# EMIF register map
Vendor: Texas Instruments
Registers are 32-bit, access per field, reset 0x0 unless marked. A register's access mark holds for its fields unless they carry their own. Offsets are as the file gives them; [hi:lo] are bit positions.

## EMIF (part 2 of 2)
0x00 EMIF_REVISION ro reset not defined — Revision number register
  [31:0] REVISION — Module revision
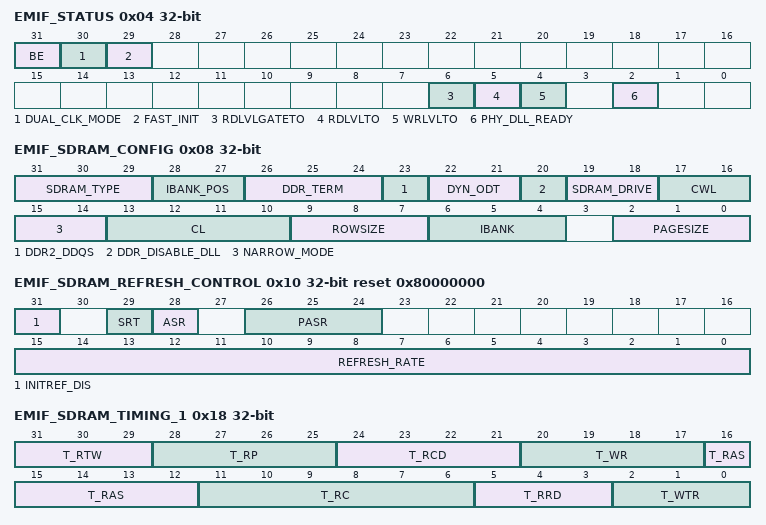
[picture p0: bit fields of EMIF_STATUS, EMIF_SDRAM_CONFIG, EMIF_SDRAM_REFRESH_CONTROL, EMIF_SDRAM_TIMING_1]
0x04 EMIF_STATUS ro — SDRAM Status Register (STATUS)
  [31] BE — Big endian mode select for 8 and 16-bit devices, set to 1 for big endian or 0 for little endian operation. In current implementation, only 32-bit devices are supported - this bit is don't care.
  [30] DUAL_CLK_MODE — Dual Clock mode. Defines whether the EMIF_L3_ICLK and EMIF_FICLK clock are asynchronous. EMIF_L3_ICLK and EMIF_FICLK clock are asynchronous, if set to 1.
  [29] FAST_INIT — Fast Init. Defines whether the EMIF fast initialization mode has been enabled. Fast initialization is enabled if set to 1.
  [6] RDLVLGATETO — Read DQS Gate Training Timeout. Value of 1 indicates read DQS gate training has timed out because read DQS gate training done was not received from the PHY.
  [5] RDLVLTO — Read Data Eye Training Timeout. Value of 1 indicates read data eye training has timed out because read data eye training done was not received from the PHY.
  [4] WRLVLTO — Write Leveling Timeout. Value of 1 indicates write leveling has timed out because write leveling done was not received from the PHY.
  [2] PHY_DLL_READY — DDR PHY Ready. The DDR PHY is ready for normal operation, if set to 1.
0x08 EMIF_SDRAM_CONFIG — SDRAM Config Register. A write to this register will cause the EMIF to start the SDRAM initialization sequence. CAUTION: This register is loaded with values by control module at device reset.
  [31:29] SDRAM_TYPE rw — SDRAM Type selection. This field is loaded from e-fuse. Set to 2 for DDR2 Set to 3 for DDR3 Set to 4 for LPDDR2 All other values are reserved.
  [28:27] IBANK_POS rw — Internal bank position. See , SDRAM Address Mapping.
  [26:24] DDR_TERM rw — DDR3 termination resistor value. Set to 0 to disable termination. For DDR3, set to 1 for RZQ/4, set to 2 for RZQ/2, set to 3 for RZQ/6, set to 4 for RZQ/12, and set to 5 for RZQ/8. All other values are reserved.
  [23] DDR2_DDQS rw — Differential DQS enable. Set to 0 for single ended DQS (Not supported). Set to 1 for differential DQS.
  [22:21] DYN_ODT rw — DDR3 Dynamic ODT.Not supported. Set to 0 to turn off dynamic ODT.
  [20] DDR_DISABLE_DLL rw — Disable DLL select. Set to 1 to disable DLL inside SDRAM.
  [19:18] SDRAM_DRIVE rw — SDRAM drive strength. For DDR2, set to 0 for normal, and set to 1 for weak drive strength. For DDR3, set to 0 for RZQ/6 and set to 1 for RZQ/7. All other values are reserved.
  [17:16] CWL rw — DDR3 CAS Write latency. Value of 0, 1, 2, and 3 (CAS write latency of 5, 6, 7, and 8) are supported. Use the lowest value supported for best performance. All other values are reserved.
  [15:14] NARROW_MODE rw — SDRAM data bus width. Set to 0 for 32-bit data bus width. Set to 1 for 16-bit data bus width. All other values are reserved.
  [13:10] CL rw — CAS Latency (referred to as read latency (RL) in some SDRAM specs). The value of this field defines the CAS latency to be used when accessing connected SDRAM devices. Values of 2, 3, 4 and 5 (CAS latency of 2, 3, 4 and 5) are supported for DDR2. Values of 2, 4, 6, 8, 10, 12 and 14 (CAS latency of 5, 6, 7, 8, 9, 10 and 11) are supported for DDR3. Values of 3, 4, 5, 6, 7, and 8 (CAS latency of 3, 4, 5, 6, 7, and 8) are supported for LPDDR2-SDRAM. The write latency (WL) is tied to the RL for the LPDDR2. See the LPDDR2 SDRAM standard. All other values are reserved.
  [9:7] ROWSIZE rw — Row Size. Defines the number of row address bits of connected SDRAM devices. Set to 0 for 9 row bits, Set to 1 for 10 row bits, Set to 2 for 11 row bits, Set to 3 for 12 row bits, Set to 4 for 13 row bits, Set to 5 for 14 row bits, Set to 6 for 15 row bits, Set to 7 for 16 row bits. This field is only used when EMIF_SDRAM_CONFIG[28:27] IBANK_POS field is set to 1, 2, or 3 or EBANK_POS field in EMIF_SDRAM_CONFIG_2 register is set to 1.
  [6:4] IBANK rw — Internal Bank setup. Defines number of banks inside connected SDRAM devices. Set to 0 for 1 bank, Set to 1 for 2 banks, Set to 2 for 4 banks, Set to 3 for 8 banks. All other values are reserved.
  [2:0] PAGESIZE rw — Page Size. Defines the internal page size of connected SDRAM devices. Set to 0 for 256-word page (8 column bits), Set to 1 for 512-word page (9 column bits), Set to 2 for 1024-word page (10 column bits), Set to 3 for 2048-word page (11 column bits). All other values are reserved.
0x0C EMIF_SDRAM_CONFIG_2 — SDRAM Config Register 2 CAUTION: This register is loaded with values by control module at device reset.
  [27] EBANK_POS rw — External bank position. Set to 0 to assign external bank address bits from lower OCP address. Set to 1 to assign external bank address bits from higher OCP address bits. See, SDRAM Address Mapping.
0x10 EMIF_SDRAM_REFRESH_CONTROL reset 0x80000000 — SDRAM Refresh Control Register
  [31] INITREF_DIS rw — Initialization and Refresh disable. When set to 1, EMIF will disable SDRAM initialization and refreshes, but will carry out SDRAM write/read transactions.
  [29] SRT rw — DDR3 Self Refresh temperature range. Set to 0 for normal operating temperature range and set to 1 for extended operating temperature range when the ASR field is set to 0. This bit must be set to 0 if the ASR field is set to 1. A write to this field will cause the EMIF to start the SDRAM initialization sequence.
  [28] ASR rw — DDR3 Auto Self Refresh enable. Set to 1 for auto Self Refresh enable. Set to 0 for manual Self Refresh reference indicated by the SRT field. A write to this field will cause the EMIF to start the SDRAM initialization sequence.
  [26:24] PASR rw — Partial Array Self Refresh. These bits get loaded into the Extended Mode Register of DDR3 during initialization. For DDR3, set to 0 for full array, set to 1 or 5 for 1/2 array, set to 2 or 6 for 1/4 array, set to 3 or 7 for 1/8 array, and set to 4 for 3/4 array to be refreshed. All other values are reserved. A write to this field will cause the EMIF to start the SDRAM initialization sequence.
  [15:0] REFRESH_RATE rw — Refresh Rate. Value in this field is used to define the rate at which connected SDRAM devices will be refreshed. SDRAM refresh rate = REFRESH_RATE / EMIF_PHY_FCLK. A 533-MHz DDR clock rate system that requires a 7.8 µs refresh rate would need 7.8 × 533 = 4157 or 0x103D value to be written. To avoid lock-up situations, the programmer must not program REFRESH_RATE &lt; (6 × EMIF_SDRAM_TIMING_3[12:4] T_RFC).
0x14 EMIF_SDRAM_REFRESH_CONTROL_SHADOW — SDRAM Refresh Control Shadow Register
  [15:0] REFRESH_RATE_SHDW rw — Shadow field for REFRESH_RATE. This field is loaded intoEMIF_SDRAM_REFRESH_CONTROL[15:0] REFRESH_RATE field when SIdleAck is asserted.
0x18 EMIF_SDRAM_TIMING_1 rw — SDRAM Timing 1 Register. If this register is byte written, care must be taken that all the fields are written before performing any accesses to the SDRAM.
  [31:29] T_RTW — Minimum number of DDR clock cycles between Read to Write data phases, minus one.
  [28:25] T_RP — Minimum number of DDR clock cycles from Precharge to Activate or Refresh, minus one.
  [24:21] T_RCD — Minimum number of DDR clock cycles from Activate to Read or Write, minus one.
  [20:17] T_WR — Minimum number of DDR clock cycles from last Write transfer to Precharge, minus one.
  [16:12] T_RAS — Minimum number of DDR clock cycles from Activate to Precharge, minus one. T_RAS value needs to be bigger than or equal to T_RDC value.
  [11:6] T_RC — Minimum number of DDR clock cycles from Activate to Activate, minus one.
  [5:3] T_RRD — Minimum number of DDR clock cycles from Activate to Activate for a different bank, minus one. For an 8-bank, this field must be equal to ((tFAW / (4 × tCK)) - 1).
  [2:0] T_WTR — Minimum number of DDR clock cycles from last Write to Read, minus one.
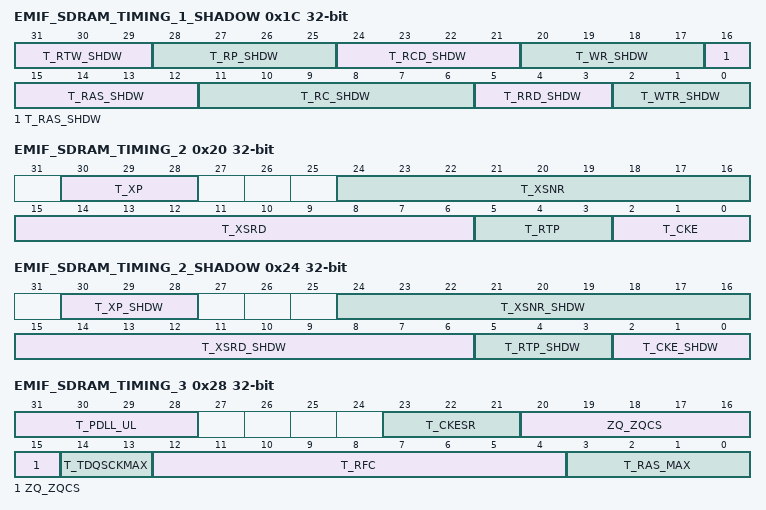
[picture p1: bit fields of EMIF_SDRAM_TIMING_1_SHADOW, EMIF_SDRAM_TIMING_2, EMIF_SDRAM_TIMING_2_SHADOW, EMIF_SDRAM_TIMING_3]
0x1C EMIF_SDRAM_TIMING_1_SHADOW rw — SDRAM Timing 1 Shadow Register
  [31:29] T_RTW_SHDW — Shadow field for T_RTW. This field is loaded intoEMIF_SDRAM_TIMING_1[31:29] T_RTW field when SIdleAck is asserted.
  [28:25] T_RP_SHDW — Shadow field for T_RP. This field is loaded intoEMIF_SDRAM_TIMING_1[28:25] T_RP field when SIdleAck is asserted.
  [24:21] T_RCD_SHDW — Shadow field for T_RCD. This field is loaded intoEMIF_SDRAM_TIMING_1[24:21] T_RCD field when SIdleAck is asserted.
  [20:17] T_WR_SHDW — Shadow field for T_WR. This field is loaded intoEMIF_SDRAM_TIMING_1[20:17] T_WR field when SIdleAck is asserted.
  [16:12] T_RAS_SHDW — Shadow field for T_RAS. This field is loaded intoEMIF_SDRAM_TIMING_1[16:12] T_RAS field when SIdleAck is asserted.
  [11:6] T_RC_SHDW — Shadow field for T_RC. This field is loaded intoEMIF_SDRAM_TIMING_1[11:6] T_RC field when SIdleAck is asserted.
  [5:3] T_RRD_SHDW — Shadow field for T_RRD. This field is loaded intoEMIF_SDRAM_TIMING_1[5:3] T_RRD field when SIdleAck is asserted.
  [2:0] T_WTR_SHDW — Shadow field for T_WTR. This field is loaded intoEMIF_SDRAM_TIMING_1[2:0] T_WTR field when SIdleAck is asserted.
0x20 EMIF_SDRAM_TIMING_2 — SDRAM Timing 2 Register. If this register is byte written, care must be taken that all the fields are written before performing any accesses to the SDRAM.
  [30:28] T_XP rw — Minimum number of DDR clock cycles from power-down exit to any command other than a read command, minus one.
  [24:16] T_XSNR rw — Minimum number of DDR clock cycles from Self-Refresh exit to any command other than a Read command, minus one.
  [15:6] T_XSRD rw — Minimum number of DDR clock cycles from Self-Refresh exit to a Read command, minus one.
  [5:3] T_RTP rw — Minimum number of DDR clock cycles for the last read command to a Precharge command, minus one.
  [2:0] T_CKE rw — Minimum number of DDR clock cycles between CKE pin changes, minus one.
0x24 EMIF_SDRAM_TIMING_2_SHADOW — SDRAM Timing 2 Shadow Register
  [30:28] T_XP_SHDW rw — Shadow field for T_XP. This field is loaded intoEMIF_SDRAM_TIMING_2[30:28] T_XP field when SIdleAck is asserted.
  [24:16] T_XSNR_SHDW rw — Shadow field for T_XSNR. This field is loaded intoEMIF_SDRAM_TIMING_2[24:16] T_XSNR field when SIdleAck is asserted.
  [15:6] T_XSRD_SHDW rw — Shadow field for T_XSRD. This field is loaded intoEMIF_SDRAM_TIMING_2[15:6] T_XSRD field when SIdleAck is asserted.
  [5:3] T_RTP_SHDW rw — Shadow field for T_RTP. This field is loaded intoEMIF_SDRAM_TIMING_2[5:3] T_RTP field when SIdleAck is asserted.
  [2:0] T_CKE_SHDW rw — Shadow field for T_CKE. This field is loaded intoEMIF_SDRAM_TIMING_2[2:0] T_CKE field when SIdleAck is asserted.
0x28 EMIF_SDRAM_TIMING_3 — SDRAM Timing 3 Register. If this register is byte written, care must be taken that all the fields are written before performing any accesses to the SDRAM.
  [31:28] T_PDLL_UL rw — Minimum number of DDR clock cycles for PHY DLL to unlock. A value of N will be equal to N x 128 clocks.
  [23:21] T_CKESR rw — Minimum number of DDR clock cycles for which SDRAM must remain in Self Refresh, minus one.
  [20:15] ZQ_ZQCS rw — Number of DDR clock cycles for a ZQCS command, minus one.
  [14:13] T_TDQSCKMAX rw — Number of DDR clock that satisfies tDQSCKmax for LPDDR2, minus one.
  [12:4] T_RFC rw — Minimum number of DDR clock cycles from Refresh or Load Mode to Refresh or Activate, minus one.
  [3:0] T_RAS_MAX rw — Maximum number of REFRESH_RATE intervals from Activate to Precharge command. This field must be equal to ((tRASmax / tREFI)-1) rounded down to the next lower integer. Value for T_RAS_MAX can be calculated as follows: If tRASmax = 120 us and tREFI = 15.7 us, then T_RAS_MAX = ((120/15.7)-1) = 6.64. Round down to the next lower integer. Therefore, the programmed value must be 6.
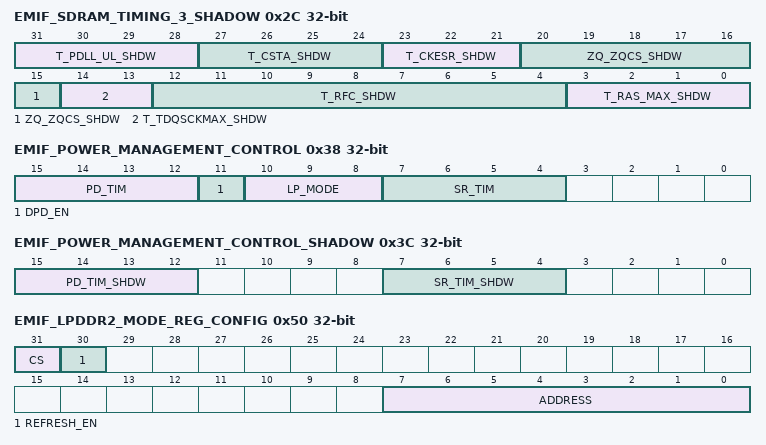
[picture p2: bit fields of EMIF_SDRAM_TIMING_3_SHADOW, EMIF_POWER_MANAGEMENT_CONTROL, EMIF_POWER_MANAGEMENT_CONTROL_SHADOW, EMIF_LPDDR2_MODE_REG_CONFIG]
0x2C EMIF_SDRAM_TIMING_3_SHADOW rw — SDRAM Timing 3 Shadow Register
  [31:28] T_PDLL_UL_SHDW — Shadow field for T_PDLL_UL. This field is loaded into T_PDLL_UL field inEMIF_SDRAM_TIMING_3 register when SIdleAck is asserted.
  [27:24] T_CSTA_SHDW — Shadow field for T_CSTA. This field is loaded into T_CSTA field inEMIF_SDRAM_TIMING_3 register when SIdleAck is asserted.
  [23:21] T_CKESR_SHDW — Shadow field for T_CKESR. This field is loaded into T_CKESR field inEMIF_SDRAM_TIMING_3 register when SIdleAck is asserted.
  [20:15] ZQ_ZQCS_SHDW — Shadow field for ZQ_ZQCS. This field is loaded into ZQ_ZQCS field inEMIF_SDRAM_TIMING_3 register when SIdleAck is asserted.
  [14:13] T_TDQSCKMAX_SHDW — Shadow field for T_TDQSCKMAX. This field is loaded intoEMIF_SDRAM_TIMING_3[14:13] T_TDQSCKMAX field when SIdleAck is asserted.
  [12:4] T_RFC_SHDW — Shadow field for T_RFC. This field is loaded intoEMIF_SDRAM_TIMING_3[12:4] T_RFC when SIdleAck is asserted.
  [3:0] T_RAS_MAX_SHDW — Shadow field for T_RAS_MAX. This field is loaded intoEMIF_SDRAM_TIMING_3[3:0] T_RAS_MAX field when SIdleAck is asserted.
0x30 EMIF_LPDDR2_NVM_TIMING rw — NOTE: This register is not supported. It is kept only for code compatibility.
0x34 EMIF_LPDDR2_NVM_TIMING_SHADOW rw — NOTE: This register is not supported. It is kept only for code compatibility.
0x38 EMIF_POWER_MANAGEMENT_CONTROL — Power Management Control Register. Updating the *_TIM fields must be followed by at least one access to SDRAM for the new value to take an effect.
  [15:12] PD_TIM rw — Power Management timer for Power-Down. The EMIF will put the external SDRAM in Power-Down mode after the EMIF is idle for these number of DDR clock cycles and if LP_MODE field is set to 4. Set to 0 to immediately enter Power-Down mode. Set to 1 for 16 clocks, set to 2 for 32 clocks, set to 3 for 64 clocks, set to 4 for 128 clocks, set to 5 for 256 clocks, set to 6 for 512 clocks, set to 7 for 1024 clocks, set to 8 for 2048 clocks, set to 9 for 4096 clocks, set to 10 for 8192 clocks, set to 11 for 16384 clocks, set to 12 for 32768 clocks, set to 13 for 65536 clocks, set to 14 for 131072 clocks, and set to 15 for 262144 clocks.
  [11] DPD_EN rw — Deep Power Down enable. Set to 0 for normal operation. Set to 1 to enter deep power-down mode. This mode will override the LP_MODE field setting.
  [10:8] LP_MODE rw — Automatic Power Management enable. 0x0: Disable automatic power management 0x1: Reserved 0x2: Self Refresh mode 0x3: Disable automatic power management 0x4: Power-Down mode All other values disable automatic power management.
  [7:4] SR_TIM rw — Power Management timer for Self Refresh. The EMIF will put the external SDRAM in Self Refresh mode after the EMIF is idle for these number of DDR clock cycles and if LP_MODE field is set to 2. Set to 0 to immediately enter Self Refresh mode. Set to 1 for 16 clocks, set to 2 for 32 clocks, set to 3 for 64 clocks, set to 4 for 128 clocks, set to 5 for 256 clocks, set to 6 for 512 clocks, set to 7 for 1024 clocks, set to 8 for 2048 clocks, set to 9 for 4096 clocks, set to 10 for 8192 clocks, set to 11 for 16384 clocks, set to 12 for 32768 clocks, set to 13 for 65536 clocks, set to 14 for 131072 clocks, and set to 15 for 262144 clocks.
0x3C EMIF_POWER_MANAGEMENT_CONTROL_SHADOW — Power Management Control Shadow Register
  [15:12] PD_TIM_SHDW rw — Shadow field for PD_TIM. This field is loaded into PD_TIM field inEMIF_POWER_MANAGEMENT_CONTROL register when SIdleAck is asserted.
  [7:4] SR_TIM_SHDW rw — Shadow field for SR_TIM. This field is loaded into SR_TIM field inEMIF_POWER_MANAGEMENT_CONTROL register when SIdleAck is asserted.
0x40 EMIF_LPDDR2_MODE_REG_DATA — LPDDR2 Mode Reg Data Register A write to this register will cause a Mode Register write command to be sent to the LPDDR2 device with write data as specified in the VALUE_0 field. The address and chip select are taken from the register. A read to this register will cause a Mode Register read command to be sent to the LPDDR2 device. The address and chip select are taken from the register. The read data will appear in VALUE_0 field.
  [6:0] VALUE_0 rw — Mode register value.
0x50 EMIF_LPDDR2_MODE_REG_CONFIG — LPDDR2 Mode Reg Config Register
  [31] CS rw — Chip select to issue mode register command. Set to 0 for CSN0.
  [30] REFRESH_EN rw — Refresh Enable after MRW write. If aEMIF_LPDDR2_MODE_REG_DATA register write occurs with this bit set to 1, the refresh operations will commence.
  [7:0] ADDRESS rw — Mode register address.
0x54 EMIF_OCP_CONFIG reset 0x7770000 — OCP Config Register
  [27:24] SYS_THRESH_MAX rw — System OCP Threshold Maximum. The number of commands the system interface can consume in the command FIFO. The value is used to determine when to stop future request, writing a zero will reserve no space for the associated interface. In the event the value is set to zero and a request is seen for that interface, the command FIFO will assume a value of 1.
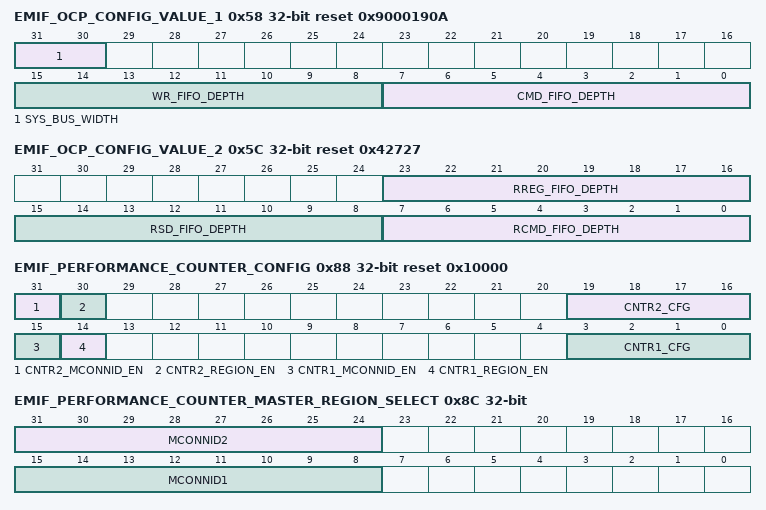
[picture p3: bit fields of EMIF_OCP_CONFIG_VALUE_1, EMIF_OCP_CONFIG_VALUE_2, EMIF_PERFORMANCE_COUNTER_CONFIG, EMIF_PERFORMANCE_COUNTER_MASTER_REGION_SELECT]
0x58 EMIF_OCP_CONFIG_VALUE_1 ro reset 0x9000190A — OCP Config Value 1 Register
  [31:30] SYS_BUS_WIDTH — System OCP data bus width 0 = 32-bit wide, 1 = 64-bit wide, 2 = 128-bit wide, 3 = Reserved
  [15:8] WR_FIFO_DEPTH — Write Data FIFO depth
  [7:0] CMD_FIFO_DEPTH — Command FIFO depth
0x5C EMIF_OCP_CONFIG_VALUE_2 ro reset 0x42727 — OCP Config Value 2 Register
  [23:16] RREG_FIFO_DEPTH — Register Read Data FIFO depth
  [15:8] RSD_FIFO_DEPTH — SDRAM Read Data FIFO depth
  [7:0] RCMD_FIFO_DEPTH — Read Command FIFO depth
0x60 EMIF_IODFT_TLGC reset 0x2011
  [10] RESET_PHY rw — Reset the DDR PHY. Writing 1 to this bit resets the DDR PHY. This bit will self clear to 0.
0x80 EMIF_PERFORMANCE_COUNTER_1 ro — Performance Counter 1 Register
  [31:0] COUNTER1 — 32-bit counter that can be configured as specified in theEMIF_PERFORMANCE_COUNTER_CONFIG register and EMIF_PERFORMANCE_COUNTER_MASTER_REGION_SELECT register.
0x84 EMIF_PERFORMANCE_COUNTER_2 ro — Performance Counter 2 Register
  [31:0] COUNTER2 — 32-bit counter that can be configured as specified in theEMIF_PERFORMANCE_COUNTER_CONFIG register and EMIF_PERFORMANCE_COUNTER_MASTER_REGION_SELECT register.
0x88 EMIF_PERFORMANCE_COUNTER_CONFIG reset 0x10000 — Performance Counter Config Register
  [31] CNTR2_MCONNID_EN rw — MConnID filter enable forEMIF_PERFORMANCE_COUNTER_2 register.
  [30] CNTR2_REGION_EN rw — Chip Select filter enable forEMIF_PERFORMANCE_COUNTER_2 register.
  [19:16] CNTR2_CFG rw — Filter configuration forEMIF_PERFORMANCE_COUNTER_2. Refer to for details.
  [15] CNTR1_MCONNID_EN rw — MConnID filter enable forEMIF_PERFORMANCE_COUNTER_1 register.
  [14] CNTR1_REGION_EN rw — Chip Select filter enable forEMIF_PERFORMANCE_COUNTER_1 register.
  [3:0] CNTR1_CFG rw — Filter configuration forEMIF_PERFORMANCE_COUNTER_1. Refer to for details.
0x8C EMIF_PERFORMANCE_COUNTER_MASTER_REGION_SELECT — Performance Counter Master Region Select Register The values programmed into the MCONNIDx fields are those in the ConnID Valuestable in , Interconnect.
  [31:24] MCONNID2 rw — MConnID forEMIF_PERFORMANCE_COUNTER_2 register.
  [15:8] MCONNID1 rw — MConnID forEMIF_PERFORMANCE_COUNTER_1 register.
0x90 EMIF_PERFORMANCE_COUNTER_TIME ro — Performance Counter Time Register. This is a free running counter.
  [31:0] TOTAL_TIME — 32-bit counter that continuously counts number for EMIF_FICLK clock cycles elapsed after EMIF is brought out of reset.
0x94 EMIF_MISC_REG
  [0] DLL_CALIB_OS rw — Phy_dll_calib one shot : Setting bit to 1 generates a phy_pll_calib pulse. Bit is self cleared when pll_calib gets generated and ack_wait has been satisfied. Software can poll to confirm completion. Uses the EMIF_DLL_CALIB_CTRL[19:16] ACK_WAIT bit field for time to wait after firing off the phy_dll_calib.
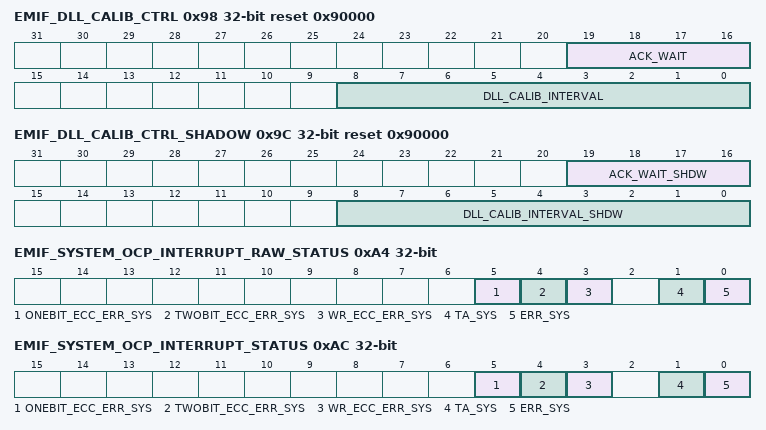
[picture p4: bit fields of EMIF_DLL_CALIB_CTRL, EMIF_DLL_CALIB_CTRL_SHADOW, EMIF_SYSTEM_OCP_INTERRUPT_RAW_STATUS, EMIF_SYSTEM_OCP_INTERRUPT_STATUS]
0x98 EMIF_DLL_CALIB_CTRL reset 0x90000 — Control register to force idle window time to generate a phy_dll_calib that can be used for updating PHY DLLs during voltage ramps. NOTE: Should always be loaded via the shadow register.
  [19:16] ACK_WAIT rw — The ack_wait determines the required wait time after a phy_dll_calib is generated before another command can be sent. Value program is in terms of EMIF_FICLK cycle count. CAUTION: 5 must be the minimum value ever programmed.
  [8:0] DLL_CALIB_INTERVAL rw — This field determines the interval between phy_dll_calib generation. This value is multiplied by a precounter of 16 EMIF_FICLK cycles. Program this field one less the value you are targeting; program 1 to achieve interval of 2 (minimum interval supported). Programming zero turns off function. Note the final intervals between dll_calib generation is also a function of ACK_WAIT. Final periodic interval is calculated by: ((DLL_CALIB_INTERVAL + 1) × 16) + ACK_WAIT
0x9C EMIF_DLL_CALIB_CTRL_SHADOW reset 0x90000 — Read Idle Control Shadow Register
  [19:16] ACK_WAIT_SHDW rw — Shadow field for ACK_WAIT. This field is loaded into ACK_WAIT field inEMIF_DLL_CALIB_CTRL register when SIdleAck is asserted
  [8:0] DLL_CALIB_INTERVAL_SHDW rw — Shadow field for DLL_CALIB_INTERVAL. This field is loaded into DLL_CALIB_INTERVAL field in theEMIF_DLL_CALIB_CTRL register when SIdleAck is asserted
0xA0 EMIF_END_OF_INTERRUPT
  [0] EOI rw — Software End Of Interrupt (EOI) control. Write 0x0 for system OCP interrupt. This field always reads 0 (no EOI memory).
0xA4 EMIF_SYSTEM_OCP_INTERRUPT_RAW_STATUS — System OCP Interrupt Raw Status Register
  [5] ONEBIT_ECC_ERR_SYS rw — Raw status of system ECC one bit error correction interrupt.
  [4] TWOBIT_ECC_ERR_SYS rw — Raw status of system ECC two bit error detection interrupt.
  [3] WR_ECC_ERR_SYS rw — Raw status of system ECC Error interrupt when a memory access is made to a non-quanta aligned location.
  [1] TA_SYS rw — Raw status of system OCP interrupt for SDRAM temperature alert. Write 1 to set the (raw) status, mostly for debug. Writing a 0 has no effect.
  [0] ERR_SYS rw — Raw status of system OCP interrupt for command or address error. Write 1 to set the (raw) status, mostly for debug. Writing a 0 has no effect.
0xAC EMIF_SYSTEM_OCP_INTERRUPT_STATUS — System OCP Interrupt Status Register
  [5] ONEBIT_ECC_ERR_SYS rw — Enabled status of system ECC one bit error correction interrupt. Write 1 to clear the status after interrupt has been serviced (raw status gets cleared, that is even if not enabled). Writing a 0 has no effect
  [4] TWOBIT_ECC_ERR_SYS rw — Enabled status of system ECC two bit error detection interrupt. Write 1 to clear the status after interrupt has been serviced (raw status gets cleared, that is even if not enabled). Writing a 0 has no effect.
  [3] WR_ECC_ERR_SYS rw — Enabled status of system ECC Error interrupt when a memory access is made to a non-quanta aligned location. Write 1 to clear the status after interrupt has been serviced (raw status gets cleared, that is even if not enabled). Writing a 0 has no effect.
  [1] TA_SYS rw — Enabled status of system OCP interrupt for SDRAM temperature alert. Write 1 to clear the status after interrupt has been serviced (raw status gets cleared, that is, even if not enabled). Writing a 0 has no effect.
  [0] ERR_SYS rw — Enabled status of system OCP interrupt interrupt for command or address error. Write 1 to clear the status after interrupt has been serviced (raw status gets cleared, that is, even if not enabled). Writing a 0 has no effect.
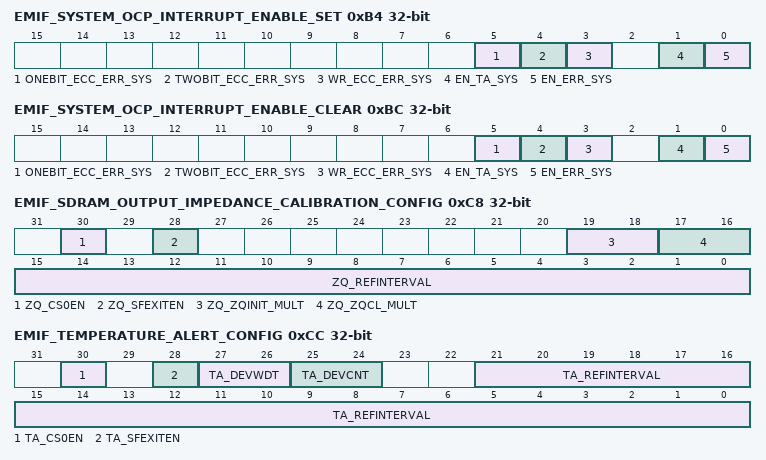
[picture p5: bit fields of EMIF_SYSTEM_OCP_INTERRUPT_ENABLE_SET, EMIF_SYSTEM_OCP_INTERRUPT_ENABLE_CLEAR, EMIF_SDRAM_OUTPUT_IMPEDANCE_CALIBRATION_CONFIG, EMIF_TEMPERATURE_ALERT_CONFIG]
0xB4 EMIF_SYSTEM_OCP_INTERRUPT_ENABLE_SET access not given — System OCP Interrupt Enable Set Register
  [5] ONEBIT_ECC_ERR_SYS — Enabled status of sysem ECC one bit error correction interrupt. Writing a 1 will enable the interrupt, and set this bit as well as the corresponding Interrupt Enable Clear Register. Writing a 0 has no effect. (access RW W1toSet)
  [4] TWOBIT_ECC_ERR_SYS — Enabled status of system ECC two bit error detection interrupt. Writing a 1 will enable the interrupt, and set this bit as well as the corresponding Interrupt Enable Clear Register. Writing a 0 has no effect. (access RW W1toSet)
  [3] WR_ECC_ERR_SYS — Enabled status of system ECC Error interrupt when a memory access is made to a non-quanta aligned location. Writing a 1 will enable the interrupt, and set this bit as well as the corresponding Interrupt Enable Clear Register. Writing a 0 has no effect. (access RW W1toSet)
  [1] EN_TA_SYS — Enable set for system OCP interrupt for SDRAM temperature alert. . Writing a 1 will enable the interrupt, and set this bit as well as the corresponding Interrupt Enable Clear Register. Writing a 0 has no effect. (access RW W1toSet)
  [0] EN_ERR_SYS — Enable set for system OCP interrupt for command or address error. Writing a 1 will enable the interrupt, and set this bit as well as the corresponding Interrupt Enable Clear Register. Writing a 0 has no effect. (access RW W1toSet)
0xBC EMIF_SYSTEM_OCP_INTERRUPT_ENABLE_CLEAR access not given — System OCP Interrupt Enable Clear Register
  [5] ONEBIT_ECC_ERR_SYS — Enabled status of system ECC one bit error correction interrupt. Writing a 1 will disable the interrupt, and clear this bit as well as the corresponding Interrupt Enable Set Register. Writing a 0 has no effect. (access RW W1toClr)
  [4] TWOBIT_ECC_ERR_SYS — Enabled status of system ECC two bit error detection interrupt. Writing a 1 will disable the interrupt, and clear this bit as well as the corresponding Interrupt Enable Set Register. Writing a 0 has no effect. (access RW W1toClr)
  [3] WR_ECC_ERR_SYS — Enabled status of system ECC Error interrupt when a memory access is made to a non-quanta aligned location. Writing a 1 will disable the interrupt, and clear this bit as well as the corresponding Interrupt Enable Set Register. Writing a 0 has no effect. (access RW W1toClr)
  [1] EN_TA_SYS — Enable clear for system OCP interrupt for SDRAM temperature alert. Writing a 1 will disable the interrupt, and clear this bit as well as the corresponding Interrupt Enable Set Register. Writing a 0 has no effect. (access RW W1toClr)
  [0] EN_ERR_SYS — Enable clear for system OCP interrupt for command or address error. Writing a 1 will disable the interrupt, and clear this bit as well as the corresponding Interrupt Enable Set Register. Writing a 0 has no effect. (access RW W1toClr)
0xC8 EMIF_SDRAM_OUTPUT_IMPEDANCE_CALIBRATION_CONFIG — SDRAM Output Impedance Calibration Config Register
  [30] ZQ_CS0EN rw — Writing a 1 enables ZQ calibration for CSN0.
  [28] ZQ_SFEXITEN rw — Writing a 1 enables the issuing of ZQCL on Self-Refresh, Active Power-Down, and Precharge Power-Down exit.
  [19:18] ZQ_ZQINIT_MULT rw — Indicates the number of ZQCL durations that make up a ZQINIT duration, minus one.
  [17:16] ZQ_ZQCL_MULT rw — Indicates the number of ZQCS intervals that make up a ZQCL duration, minus one. ZQCS interval is defined by ZQ_ZQCS inEMIF_SDRAM_TIMING_3.
  [15:0] ZQ_REFINTERVAL rw — Number of refresh periods between ZQCS commands. This field supports between one refresh period to 256 ms between ZQCS calibration commands. Refresh period is defined by REFRESH_RATE inEMIF_SDRAM_REFRESH_CONTROL register.
0xCC EMIF_TEMPERATURE_ALERT_CONFIG — Temperature Alert Config Register
  [30] TA_CS0EN rw — Writing a 1 enables temperature alert polling for CSN0.
  [28] TA_SFEXITEN rw — Temperature Alert Poll on Self-Refresh, Active Power-Down, and Precharge Power-Down exit enable. Writing a 1 enables the issuing of a temperature alert poll on Self-Refresh exit.
  [27:26] TA_DEVWDT rw — This field indicates how wide a physical device is. It is used in conjunction with the TA_DEVCNT field to determine which byte lanes contain the temperature alert info. A value of 0: 8-bit wide, 1: 16- bit wide, 2: 32-bit wide. All others are reserved. If this field is set to 1 and the TA_DEVCNT field is set to 1 the byte mask for checking will be 4'b0101.
  [25:24] TA_DEVCNT rw — This field indicates which external byte lanes contain a device for temperature monitoring. A value of 0 = one device, 1 = two devices, 2 = four devices. All other reserved.
  [21:0] TA_REFINTERVAL rw — Number of refresh periods between temperature alert polls. This field supports between one refresh period to 10 seconds between temperature alert polls. Refresh period is defined by REFRESH_RATE inEMIF_SDRAM_REFRESH_CONTROL register.
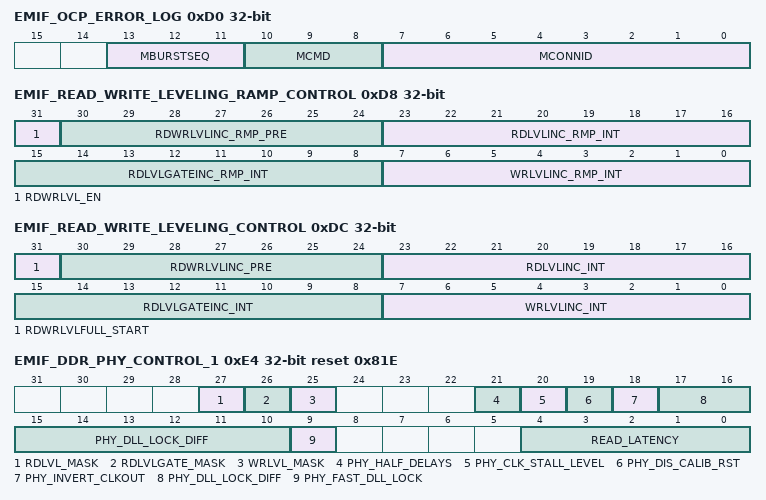
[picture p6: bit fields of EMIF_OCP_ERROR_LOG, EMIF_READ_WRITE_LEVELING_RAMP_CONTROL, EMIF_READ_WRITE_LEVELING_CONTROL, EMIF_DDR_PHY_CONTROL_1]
0xD0 EMIF_OCP_ERROR_LOG ro — OCP Error Log Register. This register is overwritten by any first error transaction once after the interrupt is serviced and cleared by writing 0x1 to the[0] ERR_SYS bit.
  [13:11] MBURSTSEQ — Addressing mode of the first errored transaction. (see, L3_MAIN Interconnect for more information)
  [10:8] MCMD — Command type of the first errored transaction. (see, L3_MAIN Interconnect for more information)
  [7:0] MCONNID — Connection ID of the first errored transaction.
0xD4 EMIF_READ_WRITE_LEVELING_RAMP_WINDOW — Read/write leveling ramp window register
  [12:0] RDWRLVLINC_RMP_WIN rw — Incremental leveling ramp window in number of refresh periods. The value programmed is minus one the required value. Refresh period is defined by REFRESH_RATE inEMIF_SDRAM_REFRESH_CONTROL register. NOTE: Incremental leveling is not supported on this device.
0xD8 EMIF_READ_WRITE_LEVELING_RAMP_CONTROL rw — Read/write leveling ramp control register
  [31] RDWRLVL_EN — Read-Write Leveling enable. Set 1 to enable leveling. Set 0 to disable leveling.
  [30:24] RDWRLVLINC_RMP_PRE — Incremental leveling pre-scalar in number of refresh periods during ramp window. The value programmed is minus one the required value. Refresh period is defined by REFRESH_RATE inEMIF_SDRAM_REFRESH_CONTROL register. NOTE: Incremental leveling is not supported on this device.
  [23:16] RDLVLINC_RMP_INT — Incremental read data eye training interval during ramp window. Number of RDWRLVLINC_RMP_PRE intervals between incremental read data eye training during ramp window. A value of 0 will disable incremental read data eye training.NOTE: Incremental leveling is not supported on this device.
  [15:8] RDLVLGATEINC_RMP_INT — Incremental read DQS gate training interval during ramp window. Number of RDWRLVLINC_RMP_PRE intervals between incremental read DQS gate training during ramp window. A value of 0 will disable incremental read DQS gate training.NOTE: Incremental leveling is not supported on this device.
  [7:0] WRLVLINC_RMP_INT — Incremental write leveling interval during ramp window. Number of RDWRLVLINC_RMP_PRE intervals between incremental write leveling during ramp window. A value of 0 will disable incremental write leveling.NOTE: Incremental leveling is not supported on this device.
0xDC EMIF_READ_WRITE_LEVELING_CONTROL rw — Read/write leveling control register
  [31] RDWRLVLFULL_START — Full leveling trigger. Writing a 1 to this field triggers full read and write leveling. This bit will self clear to 0.
  [30:24] RDWRLVLINC_PRE — Incremental leveling pre-scalar in number of refresh periods. The value programmed is minus one the required value. Refresh period is defined by REFRESH_RATE inEMIF_SDRAM_REFRESH_CONTROL register. NOTE: Incremental leveling is not supported on this device.
  [23:16] RDLVLINC_INT — Incremental read data eye training interval. Number of RDWRLVLINC_PRE intervals between incremental read data eye training. A value of 0 will disable incremental read data eye training.NOTE: Incremental leveling is not supported on this device.
  [15:8] RDLVLGATEINC_INT — Incremental read DQS gate training interval. Number of RDWRLVLINC_PRE intervals between incremental read DQS gate training. A value of 0 will disable incremental read DQS gate training.NOTE: Incremental leveling is not supported on this device.
  [7:0] WRLVLINC_INT — Incremental write leveling interval. Number of RDWRLVLINC_PRE intervals between incremental write leveling. A value of 0 will disable incremental write leveling.NOTE: Incremental leveling is not supported on this device.
0xE4 EMIF_DDR_PHY_CONTROL_1 rw reset 0x81E — PHY control register 1
  [27] RDLVL_MASK — Writing a 1 to this field will mask read data eye training during full leveling command, plus drives reg_phy_use_rd_data_eye_level control low to allow user to use programmed ratio values.
  [26] RDLVLGATE_MASK — Writing a 1 to this field will mask dqs gate training during full leveling command, plus drives reg_phy_use_rd_dqs_level control low to allow user to use programmed ratio values.
  [25] WRLVL_MASK — Writing a 1 to this field will mask write leveling training during full leveling command, plus drives reg_phy_use_wr_level control low to allow user to use programmed ratio values.
  [21] PHY_HALF_DELAYS — Adjust slave delay line delays to support 2× mode 1: 2× mode (MDLL clock is half the rate of PHY) 0: 1× mode ( MDLL clock rate is same as PHY)
  [20] PHY_CLK_STALL_LEVEL — Enable variable idle value for delay lines. Enable during normal operations to avoid differential aging in the delay lines.
  [19] PHY_DIS_CALIB_RST — Disable the dll_calib (internally generated) signal from resetting the Read Capture FIFO pointers and portions of data PHYs. Debug only. Note: dll_calib is generated by 1. EMIF_MISC_REG[0] DLL_CALIB_OS set to 1,or 2. by the PHY when it detects that the clock frequency variation has exceeded the bounds set by PHY_DLL_LOCK_DIFF or 3. periodically throughout the leveling process.
  [18] PHY_INVERT_CLKOUT — Inverts the polarity of DRAM clock. 0: core clock is passed on to DRAM 1: inverted core clock is passed on to DRAM
  [17:10] PHY_DLL_LOCK_DIFF — The maximum number of delay line taps variation while maintaining the master DLL lock. When the PHY is in locked state and the variation on the clock exceeds the variation indicated by this field, the lock signal is de-asserted and a dll_calib signal is generated. To prevent the dll_calib signal from being asserted in the middle of traffic when the clock jitter exceeds the variation, this register needs to be set to a value which will ensure that the lock will not be lost. Recommended value is 16.
  [9] PHY_FAST_DLL_LOCK — Controls master DLL to lock fast or average logic must be part of locking process. Set to 1 before OPP transition commences, and set back to 0 after OPP transition completes. 1: MDLL lock is asserted based on single sample 0: MDLL lock is asserted based on average of 16 samples.
  [4:0] READ_LATENCY — This field defines the read latency for the read data from SDRAM in number of DDR clock cycles. This field is used by the EMIF as well as the PHY. READ_LATENCY = RL + reg_phy_rdc_we_to_re -1. EMIF uses above equation to calculate reg_phy_rdc_we_to_re and forward it to the PHY. For DDR3, the true RL is used, not the decoded value. See JEDEC spec. The write latency (WL) is tied to the RL for the LPDDR2. See the LPDDR2 SDRAM standard.
